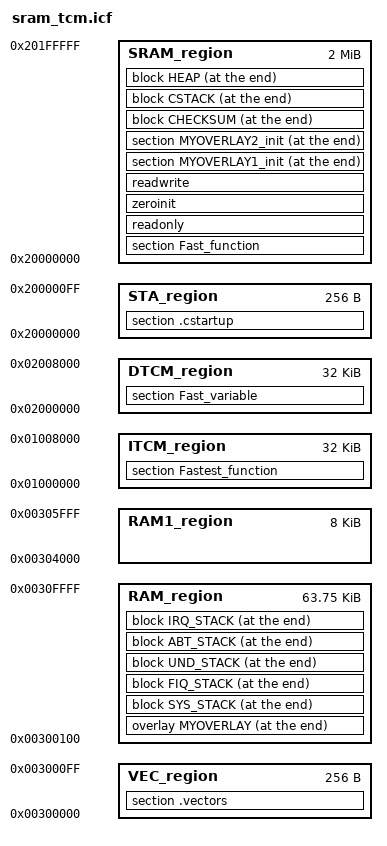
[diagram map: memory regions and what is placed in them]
/*###ICF### Section handled by ICF editor, don't touch! ****/
/*-Editor annotation file-*/
/* IcfEditorFile="$TOOLKIT_DIR$\config\ide\IcfEditor\a_v1_0.xml" */
/*-Memory Regions-*/
define symbol __ICFEDIT_region_SRAM_start__ = 0x20000000;
define symbol __ICFEDIT_region_SRAM_end__   = 0x201FFFFF;
define symbol __ICFEDIT_region_RAM1_start__   = 0x304000;
define symbol __ICFEDIT_region_RAM1_end__     = 0x305FFF;
define symbol __ICFEDIT_region_IRAM_start__   = 0x300000;
define symbol __ICFEDIT_region_IRAM_end__     = 0x30FFFF;

define symbol __ICFEDIT_region_ITCM_RAM_start__   = 0x1000000;
define symbol __ICFEDIT_region_ITCM_RAM_end__     = 0x1008000;

define symbol __ICFEDIT_region_DTCM_RAM_start__   = 0x2000000;
define symbol __ICFEDIT_region_DTCM_RAM_end__     = 0x2008000;

/*-Sizes-*/
define symbol __ICFEDIT_size_startup__  = 0x100;
define symbol __ICFEDIT_size_vectors__  = 0x100;
define symbol __ICFEDIT_size_cstack__   = 0x2000;
define symbol __ICFEDIT_size_sysstack__ = 0x60;
define symbol __ICFEDIT_size_irqstack__ = 0x60;
define symbol __ICFEDIT_size_fiqstack__ = (3*4);
define symbol __ICFEDIT_size_abtstack__ = (1*4);
define symbol __ICFEDIT_size_undstack__ = (1*4);
define symbol __ICFEDIT_size_heap__     = 0x0;
/*-Exports-*/
export symbol __ICFEDIT_region_SRAM_start__;
export symbol __ICFEDIT_region_IRAM_start__;
export symbol __ICFEDIT_region_IRAM_end__;
export symbol __ICFEDIT_size_startup__;
export symbol __ICFEDIT_size_vectors__;
export symbol __ICFEDIT_size_cstack__;
export symbol __ICFEDIT_size_sysstack__;
export symbol __ICFEDIT_size_irqstack__;
export symbol __ICFEDIT_size_fiqstack__;
export symbol __ICFEDIT_size_abtstack__;
export symbol __ICFEDIT_size_undstack__;
export symbol __ICFEDIT_size_heap__;
export symbol __ICFEDIT_region_RAM1_start__;
export symbol __ICFEDIT_region_RAM1_end__;
/**** End of ICF editor section. ###ICF###*/

define memory mem with size = 4G;
define region STA_region =   mem:[from __ICFEDIT_region_SRAM_start__  size __ICFEDIT_size_startup__];
//define region SDRAM_region = mem:[from __ICFEDIT_region_SDRAM_start__+__ICFEDIT_size_startup__ to __ICFEDIT_region_SDRAM_end__];
define region SRAM_region = mem:[from __ICFEDIT_region_SRAM_start__ to __ICFEDIT_region_SRAM_end__];

define region VEC_region =   mem:[from __ICFEDIT_region_IRAM_start__ size __ICFEDIT_size_vectors__];

define region RAM_region =   mem:[from __ICFEDIT_region_IRAM_start__+__ICFEDIT_size_vectors__ to __ICFEDIT_region_IRAM_end__];
define region RAM1_region =  mem:[from __ICFEDIT_region_RAM1_start__ to __ICFEDIT_region_RAM1_end__];

define region ITCM_region =  mem:[from __ICFEDIT_region_ITCM_RAM_start__ to __ICFEDIT_region_ITCM_RAM_end__];
define region DTCM_region =  mem:[from __ICFEDIT_region_DTCM_RAM_start__ to __ICFEDIT_region_DTCM_RAM_end__];



define block CSTACK    with alignment = 8, size = __ICFEDIT_size_cstack__   { };
define block SYS_STACK with alignment = 8, size = __ICFEDIT_size_sysstack__ { };
define block IRQ_STACK with alignment = 8, size = __ICFEDIT_size_irqstack__ { };
define block FIQ_STACK with alignment = 8, size = __ICFEDIT_size_fiqstack__ { };
define block ABT_STACK with alignment = 8, size = __ICFEDIT_size_abtstack__ { };
define block UND_STACK with alignment = 8, size = __ICFEDIT_size_undstack__ { };
define block HEAP      with alignment = 8, size = __ICFEDIT_size_heap__     { };
keep { section MYOVERLAY1,section MYOVERLAY2 };

define overlay MYOVERLAY { section MYOVERLAY1 };
define overlay MYOVERLAY { section MYOVERLAY2 };

initialize manually { section MYOVERLAY1, section MYOVERLAY2 };




initialize by copy { section .vectors };
initialize by copy { readwrite };
initialize by copy with packing = zeros { section Fastest_function };
initialize by copy with packing = zeros { section Fast_function };

do not initialize  { section .noinit };

place in STA_region { section .cstartup };
place in VEC_region { section .vectors };

define block CHECKSUM { ro section .checksum };
/*
place at address mem:0x0300500 {overlay MYOVERLAY};
place in RAM_region  { overlay MYOVERLAY };*/
/*place at address mem:[from 0x300000 to 0x30f000]  { overlay MYOVERLAY };  */
/* place at end of RAM_region {block SYS_STACK, block IRQ_STACK,};*/
place at end of RAM_region {overlay MYOVERLAY,block SYS_STACK,block FIQ_STACK, block UND_STACK, block ABT_STACK, block IRQ_STACK};
/*place in RAM1_region {section Fast_variable, section Fastest_function};*/
place in ITCM_region {section Fastest_function};
place in DTCM_region {section Fast_variable};

/* place at address mem:0x0803F000 {readonly section .checksum};*/
place in SRAM_region {section Fast_function, readonly, zeroinit, readwrite};

place at end of SRAM_region {section MYOVERLAY1_init, section MYOVERLAY2_init,
						block CHECKSUM,block CSTACK, block HEAP };


